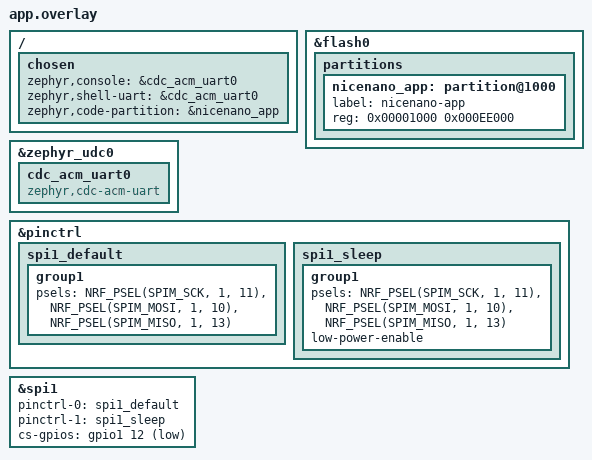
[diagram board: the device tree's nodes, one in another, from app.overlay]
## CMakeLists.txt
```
cmake_minimum_required(VERSION 3.20.0)
find_package(Zephyr REQUIRED HINTS $ENV{ZEPHYR_BASE})
project(nrf52840_nicenano_spi_flash)
target_sources(app PRIVATE src/main.c ../nrf52840_nicenano_common/ael_usb.c)
```

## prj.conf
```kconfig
# nice!nano onboard SPI flash — Stage 2 external flash test
# Reads JEDEC ID from onboard MX25R6435F (8 MB) via SPI1.
# Expected JEDEC ID: 0xC2 0x28 0x17

CONFIG_GPIO=y
CONFIG_SERIAL=y
CONFIG_CONSOLE=y
CONFIG_UART_CONSOLE=y
CONFIG_STDOUT_CONSOLE=y
CONFIG_PRINTK=y

# USB CDC-ACM console
CONFIG_USB_DEVICE_STACK_NEXT=y
CONFIG_USBD_CDC_ACM_CLASS=y
CONFIG_UART_LINE_CTRL=y
CONFIG_HWINFO=y

# SPI
CONFIG_SPI=y

# UF2 output
CONFIG_BUILD_OUTPUT_UF2=y
CONFIG_BUILD_OUTPUT_UF2_FAMILY_ID="0x239A00B3"
CONFIG_FLASH_LOAD_OFFSET=0x1000
CONFIG_FLASH_LOAD_SIZE=0xEE000
```

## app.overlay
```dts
/*
 * SPI1: SCK=P1.11, MOSI=P1.10, MISO=P1.13, CS=P1.12
 * Onboard MX25R6435F 8MB SPI NOR flash (same bus as SPI loopback test).
 * No extra wiring — flash chip is hardwired to these pins on nice!nano.
 * Console: USB CDC
 */

/ {
    chosen {
        zephyr,console = &cdc_acm_uart0;
        zephyr,shell-uart = &cdc_acm_uart0;
        zephyr,code-partition = &nicenano_app;
    };
};

&flash0 {
    partitions {
        nicenano_app: partition@1000 {
            label = "nicenano-app";
            reg = <0x00001000 0x000EE000>;
        };
    };
};

&zephyr_udc0 {
    cdc_acm_uart0: cdc_acm_uart0 {
        compatible = "zephyr,cdc-acm-uart";
    };
};

&pinctrl {
    spi1_default: spi1_default {
        group1 {
            psels = <NRF_PSEL(SPIM_SCK,  1, 11)>,
                    <NRF_PSEL(SPIM_MOSI, 1, 10)>,
                    <NRF_PSEL(SPIM_MISO, 1, 13)>;
        };
    };
    spi1_sleep: spi1_sleep {
        group1 {
            psels = <NRF_PSEL(SPIM_SCK,  1, 11)>,
                    <NRF_PSEL(SPIM_MOSI, 1, 10)>,
                    <NRF_PSEL(SPIM_MISO, 1, 13)>;
            low-power-enable;
        };
    };
};

&spi1 {
    status = "okay";
    pinctrl-0 = <&spi1_default>;
    pinctrl-1 = <&spi1_sleep>;
    pinctrl-names = "default", "sleep";
    cs-gpios = <&gpio1 12 GPIO_ACTIVE_LOW>;
};
```

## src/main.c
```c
/*
 * AEL Stage 2 — nRF52840 nice!nano onboard SPI flash JEDEC ID test
 *
 * No extra wiring — the MX25R6435F 8MB SPI NOR flash is hardwired to:
 *   SCK=P1.11, MOSI=P1.10, MISO=P1.13, CS=P1.12
 *
 * Sends JEDEC READ ID command (0x9F) via raw SPI.
 * Expected response: 0xC2 0x28 0x17 (MX25R6435F)
 *                 or 0xC8 0x40 0x15 (GD25Q16C, some board revisions)
 *
 * Reports: [SPI_FLASH] jedec=0xXX,0xXX,0xXX PASS|FAIL
 *          AEL_SPI_FLASH_PASS|FAIL
 */

#include <zephyr/kernel.h>
#include <zephyr/sys/printk.h>
#include <zephyr/drivers/spi.h>
#include <zephyr/drivers/gpio.h>
#include <string.h>
#include "../../nrf52840_nicenano_common/ael_usb.h"

#define SPI_NODE DT_NODELABEL(spi1)

/* JEDEC READ ID command */
#define CMD_JEDEC_ID  0x9F

/* Known JEDEC IDs for nice!nano onboard flash variants */
/* MX25R6435F (8MB): C2 28 17 */
/* GD25Q16C   (2MB): C8 40 15 */
static bool jedec_known(uint8_t mfr, uint8_t type, uint8_t cap)
{
    if (mfr == 0xC2 && type == 0x28 && cap == 0x17) return true; /* MX25R6435F */
    if (mfr == 0xC8 && type == 0x40 && cap == 0x15) return true; /* GD25Q16C   */
    if (mfr == 0xC8 && type == 0x60 && cap == 0x15) return true; /* GD25Q16E   */
    /* Any non-zero, non-0xFF response is treated as flash present */
    if (mfr != 0x00 && mfr != 0xFF) return true;
    return false;
}

int main(void)
{
    ael_usb_init();
    k_msleep(1500);

    printk("AEL_SPI_FLASH_START\n");

    const struct device *spi = DEVICE_DT_GET(SPI_NODE);
    if (!device_is_ready(spi)) {
        printk("[SPI_FLASH] spi_not_ready FAIL\n");
        printk("AEL_SPI_FLASH_FAIL\n");
        while (1) {
            if (atomic_get(&ael_bl_flag)) { k_msleep(50); ael_enter_bootloader(); }
            k_msleep(5000);
            printk("AEL_SPI_FLASH_FAIL (repeat)\n");
        }
    }

    static const struct spi_config cfg = {
        .frequency = 4000000,
        .operation = SPI_WORD_SET(8) | SPI_TRANSFER_MSB | SPI_OP_MODE_MASTER,
        .slave     = 0,
        .cs        = SPI_CS_GPIOS_DT_SPEC_GET(DT_NODELABEL(spi1)),
    };

    /* TX: JEDEC READ ID cmd + 3 dummy bytes for response */
    static uint8_t tx_buf[4] = { CMD_JEDEC_ID, 0x00, 0x00, 0x00 };
    static uint8_t rx_buf[4] = { 0 };

    const struct spi_buf tx_bufs[] = {{ .buf = tx_buf, .len = sizeof(tx_buf) }};
    const struct spi_buf rx_bufs[] = {{ .buf = rx_buf, .len = sizeof(rx_buf) }};
    const struct spi_buf_set tx_set = { .buffers = tx_bufs, .count = 1 };
    const struct spi_buf_set rx_set = { .buffers = rx_bufs, .count = 1 };

    int ret = spi_transceive(spi, &cfg, &tx_set, &rx_set);
    if (ret != 0) {
        printk("[SPI_FLASH] spi_err=%d FAIL\n", ret);
        printk("AEL_SPI_FLASH_FAIL\n");
        while (1) {
            if (atomic_get(&ael_bl_flag)) { k_msleep(50); ael_enter_bootloader(); }
            k_msleep(5000);
            printk("AEL_SPI_FLASH_FAIL (repeat)\n");
        }
    }

    uint8_t mfr  = rx_buf[1];
    uint8_t type = rx_buf[2];
    uint8_t cap  = rx_buf[3];

    if (!jedec_known(mfr, type, cap)) {
        printk("[SPI_FLASH] jedec=0x%02X,0x%02X,0x%02X unknown FAIL\n",
               mfr, type, cap);
        printk("AEL_SPI_FLASH_FAIL\n");
        while (1) {
            if (atomic_get(&ael_bl_flag)) { k_msleep(50); ael_enter_bootloader(); }
            k_msleep(5000);
            printk("AEL_SPI_FLASH_FAIL (repeat)\n");
        }
    }

    printk("[SPI_FLASH] jedec=0x%02X,0x%02X,0x%02X PASS\n", mfr, type, cap);
    printk("AEL_SPI_FLASH_PASS\n");

    while (1) {
        if (atomic_get(&ael_bl_flag)) { k_msleep(50); ael_enter_bootloader(); }
        k_msleep(5000);
        printk("AEL_SPI_FLASH_PASS (repeat)\n");
    }
    return 0;
}
```
